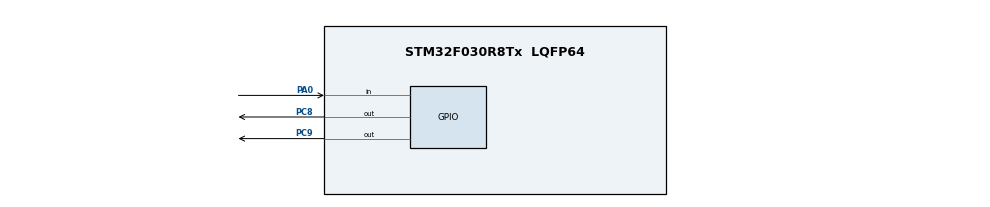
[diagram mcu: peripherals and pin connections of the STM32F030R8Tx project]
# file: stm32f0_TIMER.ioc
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Mcu.Family=STM32F0
Mcu.Name=STM32F030R8Tx
Mcu.Package=LQFP64
NVIC.TIM1_BRK_UP_TRG_COM_IRQn=true\:0\:0\:false\:false\:true\:true
PA0.Signal=GPIO_Input
PC8.Signal=GPIO_Output
PC9.Signal=GPIO_Output
ProjectManager.HeapSize=0x200
ProjectManager.StackSize=0x400
ProjectManager.TargetToolchain=MDK-ARM V5
TIM1.Period=999
TIM1.Prescaler=799
VP_TIM1_VS_ClockSourceINT.Mode=Internal
board=stm32f0_TIMER

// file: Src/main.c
/**
  ******************************************************************************
  * @file           : main.c
  * @brief          : Main program body
  ******************************************************************************
  ** This notice applies to any and all portions of this file
  * that are not between comment pairs USER CODE BEGIN and
  * USER CODE END. Other portions of this file, whether
  * inserted by the user or by software development tools
  * are owned by their respective copyright owners.
  *
  * COPYRIGHT(c) 2018 STMicroelectronics
  *
  * Redistribution and use in source and binary forms, with or without modification,
  * are permitted provided that the following conditions are met:
  *   1. Redistributions of source code must retain the above copyright notice,
  *      this list of conditions and the following disclaimer.
  *   2. Redistributions in binary form must reproduce the above copyright notice,
  *      this list of conditions and the following disclaimer in the documentation
  *      and/or other materials provided with the distribution.
  *   3. Neither the name of STMicroelectronics nor the names of its contributors
  *      may be used to endorse or promote products derived from this software
  *      without specific prior written permission.
  *
  * THIS SOFTWARE IS PROVIDED BY THE COPYRIGHT HOLDERS AND CONTRIBUTORS "AS IS"
  * AND ANY EXPRESS OR IMPLIED WARRANTIES, INCLUDING, BUT NOT LIMITED TO, THE
  * IMPLIED WARRANTIES OF MERCHANTABILITY AND FITNESS FOR A PARTICULAR PURPOSE ARE
  * DISCLAIMED. IN NO EVENT SHALL THE COPYRIGHT HOLDER OR CONTRIBUTORS BE LIABLE
  * FOR ANY DIRECT, INDIRECT, INCIDENTAL, SPECIAL, EXEMPLARY, OR CONSEQUENTIAL
  * DAMAGES (INCLUDING, BUT NOT LIMITED TO, PROCUREMENT OF SUBSTITUTE GOODS OR
  * SERVICES; LOSS OF USE, DATA, OR PROFITS; OR BUSINESS INTERRUPTION) HOWEVER
  * CAUSED AND ON ANY THEORY OF LIABILITY, WHETHER IN CONTRACT, STRICT LIABILITY,
  * OR TORT (INCLUDING NEGLIGENCE OR OTHERWISE) ARISING IN ANY WAY OUT OF THE USE
  * OF THIS SOFTWARE, EVEN IF ADVISED OF THE POSSIBILITY OF SUCH DAMAGE.
  *
  ******************************************************************************
  */
#include "main.h"
#include "stm32f0xx_hal.h"
#include "stdbool.h"

TIM_HandleTypeDef htim1;

/* USER CODE BEGIN PV */
/* Private variables ---------------------------------------------------------*/

static uint32_t flag_press_type=0;															// Flag for press type
static bool flag_press = false;																	// Flag for button press detection
static volatile uint32_t prog_button_timer = 0;									// Button press counter
static int blink = 0;																						// Blink type
static int count = 0;																						// Blink interval
//static bool flag_press = false;

/* USER CODE END PV */

void SystemClock_Config(void);
static void MX_GPIO_Init(void);
static void MX_TIM1_Init(void);

/* USER CODE BEGIN PFP */
/* Private function prototypes -----------------------------------------------*/

/* USER CODE END PFP */

int main(void)
{

  /* MCU Configuration----------------------------------------------------------*/

  /* Reset of all peripherals, Initializes the Flash interface and the Systick. */
  HAL_Init();

  /* Configure the system clock */
  SystemClock_Config();

  /* Initialize all configured peripherals */
  MX_GPIO_Init();
  MX_TIM1_Init();
  /* USER CODE BEGIN 2 */
  HAL_TIM_Base_Start_IT(&htim1);
  /* USER CODE END 2 */

  /* Infinite loop */
  while (1)
  {

  }

}

void SystemClock_Config(void)
{

  RCC_OscInitTypeDef RCC_OscInitStruct;
  RCC_ClkInitTypeDef RCC_ClkInitStruct;

    /**Initializes the CPU, AHB and APB busses clocks
    */
  RCC_OscInitStruct.OscillatorType = RCC_OSCILLATORTYPE_HSI;
  RCC_OscInitStruct.HSIState = RCC_HSI_ON;
  RCC_OscInitStruct.HSICalibrationValue = 16;
  RCC_OscInitStruct.PLL.PLLState = RCC_PLL_NONE;
  if (HAL_RCC_OscConfig(&RCC_OscInitStruct) != HAL_OK)
  {
    _Error_Handler(__FILE__, __LINE__);
  }

    /**Initializes the CPU, AHB and APB busses clocks
    */
  RCC_ClkInitStruct.ClockType = RCC_CLOCKTYPE_HCLK|RCC_CLOCKTYPE_SYSCLK
                              |RCC_CLOCKTYPE_PCLK1;
  RCC_ClkInitStruct.SYSCLKSource = RCC_SYSCLKSOURCE_HSI;
  RCC_ClkInitStruct.AHBCLKDivider = RCC_SYSCLK_DIV1;
  RCC_ClkInitStruct.APB1CLKDivider = RCC_HCLK_DIV1;

  if (HAL_RCC_ClockConfig(&RCC_ClkInitStruct, FLASH_LATENCY_0) != HAL_OK)
  {
    _Error_Handler(__FILE__, __LINE__);
  }

    /**Configure the Systick interrupt time
    */
  HAL_SYSTICK_Config(HAL_RCC_GetHCLKFreq()/1000);

    /**Configure the Systick
    */
  HAL_SYSTICK_CLKSourceConfig(SYSTICK_CLKSOURCE_HCLK);

  /* SysTick_IRQn interrupt configuration */
  HAL_NVIC_SetPriority(SysTick_IRQn, 0, 0);
}

/* TIM1 init function */
static void MX_TIM1_Init(void)
{

  TIM_ClockConfigTypeDef sClockSourceConfig;
  TIM_MasterConfigTypeDef sMasterConfig;

  htim1.Instance = TIM1;
  htim1.Init.Prescaler = 799;
  htim1.Init.CounterMode = TIM_COUNTERMODE_UP;
  htim1.Init.Period = 999;
  htim1.Init.ClockDivision = TIM_CLOCKDIVISION_DIV1;
  htim1.Init.RepetitionCounter = 0;
  htim1.Init.AutoReloadPreload = TIM_AUTORELOAD_PRELOAD_ENABLE;
  if (HAL_TIM_Base_Init(&htim1) != HAL_OK)
  {
    _Error_Handler(__FILE__, __LINE__);
  }

  sClockSourceConfig.ClockSource = TIM_CLOCKSOURCE_INTERNAL;
  if (HAL_TIM_ConfigClockSource(&htim1, &sClockSourceConfig) != HAL_OK)
  {
    _Error_Handler(__FILE__, __LINE__);
  }

  sMasterConfig.MasterOutputTrigger = TIM_TRGO_RESET;
  sMasterConfig.MasterSlaveMode = TIM_MASTERSLAVEMODE_DISABLE;
  if (HAL_TIMEx_MasterConfigSynchronization(&htim1, &sMasterConfig) != HAL_OK)
  {
    _Error_Handler(__FILE__, __LINE__);
  }

}

/** Configure pins as
        * Analog
        * Input
        * Output
        * EVENT_OUT
        * EXTI
*/
static void MX_GPIO_Init(void)
{

  GPIO_InitTypeDef GPIO_InitStruct;

  /* GPIO Ports Clock Enable */
  __HAL_RCC_GPIOA_CLK_ENABLE();
  __HAL_RCC_GPIOC_CLK_ENABLE();

  /*Configure GPIO pin Output Level */
  HAL_GPIO_WritePin(GPIOC, GPIO_PIN_8|GPIO_PIN_9, GPIO_PIN_RESET);

  /*Configure GPIO pin : PA0 */
  GPIO_InitStruct.Pin = GPIO_PIN_0;
  GPIO_InitStruct.Mode = GPIO_MODE_INPUT;
  GPIO_InitStruct.Pull = GPIO_NOPULL;
  HAL_GPIO_Init(GPIOA, &GPIO_InitStruct);

  /*Configure GPIO pins : PC8 PC9 */
  GPIO_InitStruct.Pin = GPIO_PIN_8|GPIO_PIN_9;
  GPIO_InitStruct.Mode = GPIO_MODE_OUTPUT_PP;
  GPIO_InitStruct.Pull = GPIO_NOPULL;
  GPIO_InitStruct.Speed = GPIO_SPEED_FREQ_LOW;
  HAL_GPIO_Init(GPIOC, &GPIO_InitStruct);

}

/* USER CODE BEGIN 4 */

void check_button(void)
{
	if(HAL_GPIO_ReadPin(GPIOA,GPIO_PIN_0)== 1)										//IF button pressed
	{
		flag_press = true;
		while(flag_press)
		{
			prog_button_timer++;																			//Press counter start
			if(prog_button_timer > 1000 && 														//100ms Debounce time
				 prog_button_timer < 300000)														//IF button released time less than 3 seconds(Short press)
			{
				flag_press_type = 1;
			}
			else if(prog_button_timer >= 300000)											//IF button released time more than 3 seconds(Long press)
			{
				flag_press_type = 2;
			}

			if(HAL_GPIO_ReadPin(GPIOA,GPIO_PIN_0)== 0)								//IF button released
			{
				switch(flag_press_type)
				{
					case 1:																								//Short press state
						if(blink != 21)
						{
							blink = 21;
							count = 0;
						}

						flag_press=false;
						prog_button_timer = 0;
						break;

					case 2:																								//Long press state
						if(blink != 41)
						{
							blink = 41;
							count = 0;
						}
						flag_press=false;
						prog_button_timer = 0;
						break;

					default:
						flag_press=false;
						break;

				}
			}
		}
	}
}

void Blink_Operation (void)
{
	if (blink == 0)
	{
		HAL_GPIO_WritePin(GPIOC,GPIO_PIN_8,GPIO_PIN_RESET);
		count = 0;
	}

	else if (blink == 21)																			// 2 x 1 second + 2 x 2 seconds blink
	{
		if ( (count >= 10 && count <= 20 )
			|| (count >= 30 && count <= 40 )
			|| (count >= 60 && count <= 80 ))
		{
			HAL_GPIO_WritePin(GPIOC,GPIO_PIN_8,GPIO_PIN_RESET);
		}

		else
		{
			HAL_GPIO_WritePin(GPIOC,GPIO_PIN_8,GPIO_PIN_SET);
		}
		count++;
		if(count==100)
		{
			count = 0;
			blink = 0;
		}
	}

	else if (blink == 41)																		  // 4 x 1 second + 4 x 2 seconds blink
	{
		if ( (count >= 10 && count <= 20)
			|| (count >= 30 && count <= 40)
		  || (count >= 50 && count <= 60)
			|| (count >= 70 && count <= 80)
			|| (count >= 100 && count <= 120)
			|| (count >= 140 && count <= 160)
			|| (count >= 180 && count <= 200))
		{
			HAL_GPIO_WritePin(GPIOC,GPIO_PIN_8,GPIO_PIN_RESET);
		}

		else
		{
			HAL_GPIO_WritePin(GPIOC,GPIO_PIN_8,GPIO_PIN_SET);
		}
		count++;
		if(count==220){
			count = 0;
			blink = 0;
		}
	}
}

void HAL_TIM_PeriodElapsedCallback(TIM_HandleTypeDef *htim)
{
	check_button();
	Blink_Operation();
}
/* USER CODE END 4 */

void _Error_Handler(char *file, int line)
{
  while(1)
  {
  }
}

/************************ (C) COPYRIGHT STMicroelectronics *****END OF FILE****/
